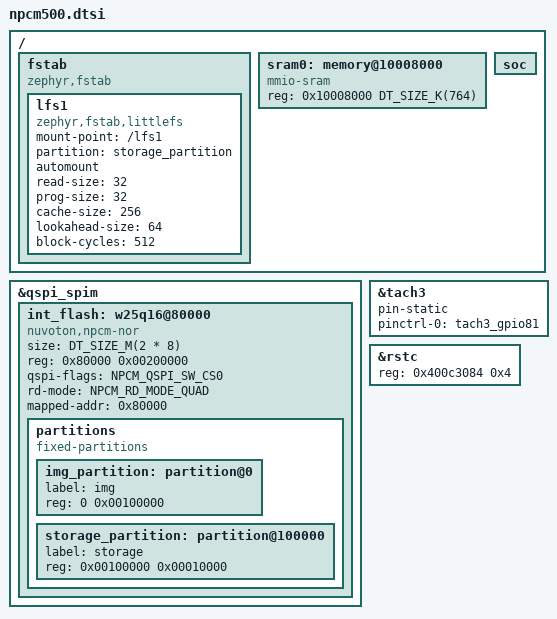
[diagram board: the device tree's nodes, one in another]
/*
 * Copyright (c) 2024 Nuvoton Technology Corporation.
 *
 * SPDX-License-Identifier: Apache-2.0
 */


/* Device tree declarations of npcm soc family */
#include <mem.h>
#include "npcm/npcm5.dtsi"

/ {
	fstab {
		compatible = "zephyr,fstab";
		lfs1: lfs1 {
			compatible = "zephyr,fstab,littlefs";
			mount-point = "/lfs1";
			partition = <&storage_partition>;
			automount;
			read-size = <32>;
			prog-size = <32>;
			cache-size = <256>;
			lookahead-size = <64>;
			block-cycles = <512>;
		};
	};

	sram0: memory@10008000 {
		compatible = "mmio-sram";
		reg = <0x10008000 DT_SIZE_K(764)>;
	};

	soc {
	};
};

&qspi_spim {
	int_flash: w25q16@80000 {
		compatible ="nuvoton,npcm-nor";
		size = <DT_SIZE_M(2 * 8)>;
		reg = <0x80000 0x00200000>;
		status = "okay";

		/* quad spi bus configuration of nor flash device */
		qspi-flags = <NPCM_QSPI_SW_CS0>;
		rd-mode = "NPCM_RD_MODE_QUAD";
		mapped-addr = <0x80000>;

		partitions {
			compatible = "fixed-partitions";
			#address-cells = <1>;
			#size-cells = <1>;

	        img_partition: partition@0 {
				label = "img";
				reg = <0 0x00100000>;
			};

	        storage_partition: partition@100000 {
				label = "storage";
				reg = <0x00100000 0x00010000>;
			};
	    };
	};
};

&tach3 {
	pin-static;
	pinctrl-0 = <&tach3_gpio81>;
	pinctrl-names = "default";
};

/* NPCM500: rstc points at the SCFG.RSTST register (offset 0x84 in
 * SCFG @ 0x400c3000).
 */
&rstc {
	reg = <0x400c3084 0x4>;
};
